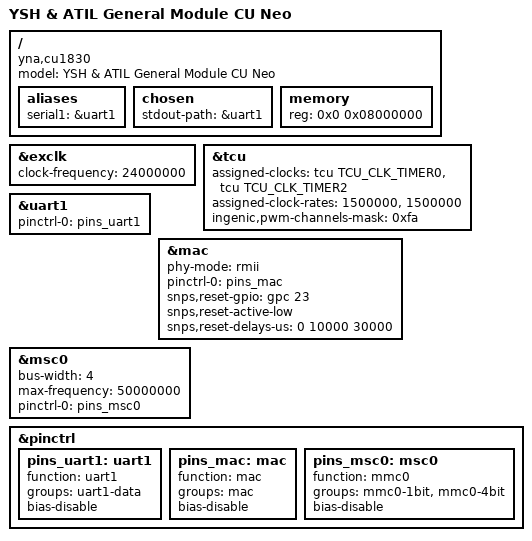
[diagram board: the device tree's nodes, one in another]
// SPDX-License-Identifier: GPL-2.0
/dts-v1/;

#include "x1830.dtsi"
#include <dt-bindings/gpio/gpio.h>
#include <dt-bindings/clock/ingenic,tcu.h>

/ {
	compatible = "yna,cu1830", "ingenic,x1830";
	model = "YSH & ATIL General Module CU Neo";

	aliases {
		serial1 = &uart1;
	};

	chosen {
		stdout-path = &uart1;
	};

	memory {
		device_type = "memory";
		reg = <0x0 0x08000000>;
	};
};

&exclk {
	clock-frequency = <24000000>;
};

&tcu {
	/* 1500 kHz for the system timer and clocksource */
	assigned-clocks = <&tcu TCU_CLK_TIMER0>, <&tcu TCU_CLK_TIMER2>;
	assigned-clock-rates = <1500000>, <1500000>;

	/* Use channel #1 for the system timer channel #2 for the clocksource */
	ingenic,pwm-channels-mask = <0xfa>;
};

&uart1 {
	status = "okay";

	pinctrl-names = "default";
	pinctrl-0 = <&pins_uart1>;
};

&mac {
	status = "okay";

	phy-mode = "rmii";

	pinctrl-names = "default";
	pinctrl-0 = <&pins_mac>;

	snps,reset-gpio = <&gpc 23 GPIO_ACTIVE_HIGH>; /* PC23 */
	snps,reset-active-low;
	snps,reset-delays-us = <0 10000 30000>;
};

&msc0 {
	status = "okay";

	bus-width = <4>;
	max-frequency = <50000000>;

	pinctrl-names = "default";
	pinctrl-0 = <&pins_msc0>;
};

&pinctrl {
	pins_uart1: uart1 {
		function = "uart1";
		groups = "uart1-data";
		bias-disable;
	};

	pins_mac: mac {
		function = "mac";
		groups = "mac";
		bias-disable;
	};

	pins_msc0: msc0 {
		function = "mmc0";
		groups = "mmc0-1bit", "mmc0-4bit";
		bias-disable;
	};
};
